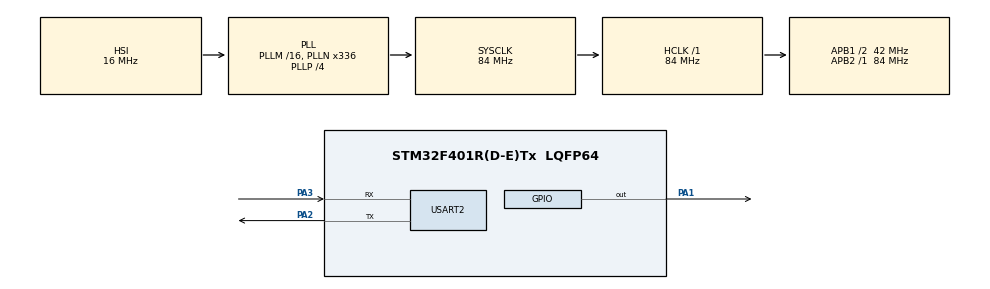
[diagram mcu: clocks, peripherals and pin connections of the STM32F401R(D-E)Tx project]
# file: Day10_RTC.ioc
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Mcu.Family=STM32F4
Mcu.Name=STM32F401R(D-E)Tx
Mcu.Package=LQFP64
NVIC.PriorityGroup=NVIC_PRIORITYGROUP_0
PA1.PinState=GPIO_PIN_SET
PA1.Signal=GPIO_Output
PA13.Mode=Serial_Wire
PA13.Signal=SYS_JTMS-SWDIO
PA14.Mode=Serial_Wire
PA14.Signal=SYS_JTCK-SWCLK
PA2.Mode=Asynchronous
PA2.Signal=USART2_TX
PA3.Mode=Asynchronous
PA3.Signal=USART2_RX
PH0\ -\ OSC_IN.Mode=HSE-External-Oscillator
PH0\ -\ OSC_IN.Signal=RCC_OSC_IN
PH1\ -\ OSC_OUT.Mode=HSE-External-Oscillator
PH1\ -\ OSC_OUT.Signal=RCC_OSC_OUT
ProjectManager.HeapSize=0x200
ProjectManager.StackSize=0x400
ProjectManager.TargetToolchain=STM32CubeIDE
RCC.48MHZClocksFreq_Value=48000000
RCC.AHBFreq_Value=84000000
RCC.APB1CLKDivider=RCC_HCLK_DIV2
RCC.APB1Freq_Value=42000000
RCC.APB1TimFreq_Value=84000000
RCC.APB2Freq_Value=84000000
RCC.APB2TimFreq_Value=84000000
RCC.CortexFreq_Value=84000000
RCC.HCLKFreq_Value=84000000
RCC.HSE_VALUE=8000000
RCC.HSI_VALUE=16000000
RCC.LSE_VALUE=32768
RCC.PLLN=336
RCC.PLLP=RCC_PLLP_DIV4
RCC.PLLQ=7
RCC.SYSCLKFreq_VALUE=84000000
RCC.SYSCLKSource=RCC_SYSCLKSOURCE_PLLCLK
RCC.VCOOutputFreq_Value=336000000
RTC.Date=11
RTC.Month=RTC_MONTH_SEPTEMBER
RTC.WeekDay=RTC_WEEKDAY_FRIDAY
TIM2.Prescaler=83
USART2.VirtualMode=VM_ASYNC
VP_RTC_VS_RTC_Activate.Mode=RTC_Enabled
VP_RTC_VS_RTC_Calendar.Mode=RTC_Calendar
VP_TIM2_VS_ClockSourceINT.Mode=Internal
board=NUCLEO-F401RE

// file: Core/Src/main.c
/* USER CODE BEGIN Header */
/**
  ******************************************************************************
  * @file           : main.c
  * @brief          : Main program body
  ******************************************************************************
  * @attention
  *
  * Copyright (c) 2026 STMicroelectronics.
  * All rights reserved.
  *
  * This software is licensed under terms that can be found in the LICENSE file
  * in the root directory of this software component.
  * If no LICENSE file comes with this software, it is provided AS-IS.
  *
  ******************************************************************************
  */
/* USER CODE END Header */
#include "main.h"

/* USER CODE BEGIN Includes */
#include "DHT11.h"
#include <stdio.h>
#include <string.h>
/* USER CODE END Includes */

RTC_HandleTypeDef hrtc;

TIM_HandleTypeDef htim2;

UART_HandleTypeDef huart2;

/* USER CODE BEGIN PV */
float temperature = 0;
float humidity = 0;

char uart_buffer[150];
RTC_TimeTypeDef sTime;
RTC_DateTypeDef sDate;
/* USER CODE END PV */

void SystemClock_Config(void);
static void MX_GPIO_Init(void);
static void MX_RTC_Init(void);
static void MX_USART2_UART_Init(void);
static void MX_TIM2_Init(void);

int main(void)
{

  /* MCU Configuration--------------------------------------------------------*/

  /* Reset of all peripherals, Initializes the Flash interface and the Systick. */
  HAL_Init();

  /* Configure the system clock */
  SystemClock_Config();

  /* Initialize all configured peripherals */
  MX_GPIO_Init();
  MX_RTC_Init();
  MX_USART2_UART_Init();
  MX_TIM2_Init();
  /* USER CODE BEGIN 2 */
  HAL_RTC_SetTime(&hrtc, &(RTC_TimeTypeDef){
      .Hours = 15,
      .Minutes = 00,
      .Seconds = 0
  }, RTC_FORMAT_BIN);

  HAL_RTC_SetDate(&hrtc, &(RTC_DateTypeDef){
      .WeekDay = RTC_WEEKDAY_FRIDAY,
      .Month = RTC_MONTH_SEPTEMBER,
      .Date = 11,
      .Year = 26
  }, RTC_FORMAT_BIN);
  /* USER CODE END 2 */

  /* Infinite loop */
  while (1)
  {
	   if (DHT11_Read(&temperature, &humidity))
	    {
	        HAL_RTC_GetTime(&hrtc, &sTime, RTC_FORMAT_BIN);
	        HAL_RTC_GetDate(&hrtc, &sDate, RTC_FORMAT_BIN);

	        sprintf(uart_buffer,
	                "Date: %02d/%02d/20%02d | Time: %02d:%02d:%02d\r\n"
	                "Temperature: %.1f C | Humidity: %.1f %%\r\n\r\n",
	                sDate.Date,
	                sDate.Month,
	                sDate.Year,
	                sTime.Hours,
	                sTime.Minutes,
	                sTime.Seconds,
	                temperature,
	                humidity);

	        HAL_UART_Transmit(&huart2,
	                          (uint8_t *)uart_buffer,
	                          strlen(uart_buffer),
	                          HAL_MAX_DELAY);
	    }
	    else
	    {
	        HAL_UART_Transmit(&huart2,
	                          (uint8_t *)"DHT11 Read Error\r\n",
	                          strlen("DHT11 Read Error\r\n"),
	                          HAL_MAX_DELAY);
	    }

	    HAL_Delay(2000);
	}

  }

void SystemClock_Config(void)
{
  RCC_OscInitTypeDef RCC_OscInitStruct = {0};
  RCC_ClkInitTypeDef RCC_ClkInitStruct = {0};

  /** Configure the main internal regulator output voltage
  */
  __HAL_RCC_PWR_CLK_ENABLE();
  __HAL_PWR_VOLTAGESCALING_CONFIG(PWR_REGULATOR_VOLTAGE_SCALE2);

  /** Initializes the RCC Oscillators according to the specified parameters
  * in the RCC_OscInitTypeDef structure.
  */
  RCC_OscInitStruct.OscillatorType = RCC_OSCILLATORTYPE_HSI|RCC_OSCILLATORTYPE_LSI;
  RCC_OscInitStruct.HSIState = RCC_HSI_ON;
  RCC_OscInitStruct.HSICalibrationValue = RCC_HSICALIBRATION_DEFAULT;
  RCC_OscInitStruct.LSIState = RCC_LSI_ON;
  RCC_OscInitStruct.PLL.PLLState = RCC_PLL_ON;
  RCC_OscInitStruct.PLL.PLLSource = RCC_PLLSOURCE_HSI;
  RCC_OscInitStruct.PLL.PLLM = 16;
  RCC_OscInitStruct.PLL.PLLN = 336;
  RCC_OscInitStruct.PLL.PLLP = RCC_PLLP_DIV4;
  RCC_OscInitStruct.PLL.PLLQ = 7;
  if (HAL_RCC_OscConfig(&RCC_OscInitStruct) != HAL_OK)
  {
    Error_Handler();
  }

  /** Initializes the CPU, AHB and APB buses clocks
  */
  RCC_ClkInitStruct.ClockType = RCC_CLOCKTYPE_HCLK|RCC_CLOCKTYPE_SYSCLK
                              |RCC_CLOCKTYPE_PCLK1|RCC_CLOCKTYPE_PCLK2;
  RCC_ClkInitStruct.SYSCLKSource = RCC_SYSCLKSOURCE_PLLCLK;
  RCC_ClkInitStruct.AHBCLKDivider = RCC_SYSCLK_DIV1;
  RCC_ClkInitStruct.APB1CLKDivider = RCC_HCLK_DIV2;
  RCC_ClkInitStruct.APB2CLKDivider = RCC_HCLK_DIV1;

  if (HAL_RCC_ClockConfig(&RCC_ClkInitStruct, FLASH_LATENCY_2) != HAL_OK)
  {
    Error_Handler();
  }
}

static void MX_RTC_Init(void)
{

  RTC_TimeTypeDef sTime = {0};
  RTC_DateTypeDef sDate = {0};

  /** Initialize RTC Only
  */
  hrtc.Instance = RTC;
  hrtc.Init.HourFormat = RTC_HOURFORMAT_24;
  hrtc.Init.AsynchPrediv = 127;
  hrtc.Init.SynchPrediv = 255;
  hrtc.Init.OutPut = RTC_OUTPUT_DISABLE;
  hrtc.Init.OutPutPolarity = RTC_OUTPUT_POLARITY_HIGH;
  hrtc.Init.OutPutType = RTC_OUTPUT_TYPE_OPENDRAIN;
  if (HAL_RTC_Init(&hrtc) != HAL_OK)
  {
    Error_Handler();
  }

  /** Initialize RTC and set the Time and Date
  */
  sTime.Hours = 0x0;
  sTime.Minutes = 0x0;
  sTime.Seconds = 0x0;
  sTime.DayLightSaving = RTC_DAYLIGHTSAVING_NONE;
  sTime.StoreOperation = RTC_STOREOPERATION_RESET;
  if (HAL_RTC_SetTime(&hrtc, &sTime, RTC_FORMAT_BCD) != HAL_OK)
  {
    Error_Handler();
  }
  sDate.WeekDay = RTC_WEEKDAY_FRIDAY;
  sDate.Month = RTC_MONTH_SEPTEMBER;
  sDate.Date = 0x11;
  sDate.Year = 0x0;

  if (HAL_RTC_SetDate(&hrtc, &sDate, RTC_FORMAT_BCD) != HAL_OK)
  {
    Error_Handler();
  }

}

static void MX_TIM2_Init(void)
{

  TIM_ClockConfigTypeDef sClockSourceConfig = {0};
  TIM_MasterConfigTypeDef sMasterConfig = {0};

  htim2.Instance = TIM2;
  htim2.Init.Prescaler = 83;
  htim2.Init.CounterMode = TIM_COUNTERMODE_UP;
  htim2.Init.Period = 4294967295;
  htim2.Init.ClockDivision = TIM_CLOCKDIVISION_DIV1;
  htim2.Init.AutoReloadPreload = TIM_AUTORELOAD_PRELOAD_DISABLE;
  if (HAL_TIM_Base_Init(&htim2) != HAL_OK)
  {
    Error_Handler();
  }
  sClockSourceConfig.ClockSource = TIM_CLOCKSOURCE_INTERNAL;
  if (HAL_TIM_ConfigClockSource(&htim2, &sClockSourceConfig) != HAL_OK)
  {
    Error_Handler();
  }
  sMasterConfig.MasterOutputTrigger = TIM_TRGO_RESET;
  sMasterConfig.MasterSlaveMode = TIM_MASTERSLAVEMODE_DISABLE;
  if (HAL_TIMEx_MasterConfigSynchronization(&htim2, &sMasterConfig) != HAL_OK)
  {
    Error_Handler();
  }

}

static void MX_USART2_UART_Init(void)
{

  huart2.Instance = USART2;
  huart2.Init.BaudRate = 115200;
  huart2.Init.WordLength = UART_WORDLENGTH_8B;
  huart2.Init.StopBits = UART_STOPBITS_1;
  huart2.Init.Parity = UART_PARITY_NONE;
  huart2.Init.Mode = UART_MODE_TX_RX;
  huart2.Init.HwFlowCtl = UART_HWCONTROL_NONE;
  huart2.Init.OverSampling = UART_OVERSAMPLING_16;
  if (HAL_UART_Init(&huart2) != HAL_OK)
  {
    Error_Handler();
  }

}

static void MX_GPIO_Init(void)
{
  GPIO_InitTypeDef GPIO_InitStruct = {0};

  /* GPIO Ports Clock Enable */
  __HAL_RCC_GPIOH_CLK_ENABLE();
  __HAL_RCC_GPIOA_CLK_ENABLE();

  /*Configure GPIO pin Output Level */
  HAL_GPIO_WritePin(GPIOA, GPIO_PIN_1, GPIO_PIN_SET);

  /*Configure GPIO pin : PA1 */
  GPIO_InitStruct.Pin = GPIO_PIN_1;
  GPIO_InitStruct.Mode = GPIO_MODE_OUTPUT_PP;
  GPIO_InitStruct.Pull = GPIO_NOPULL;
  GPIO_InitStruct.Speed = GPIO_SPEED_FREQ_LOW;
  HAL_GPIO_Init(GPIOA, &GPIO_InitStruct);

}

void Error_Handler(void)
{
  __disable_irq();
  while (1)
  {
  }
}
